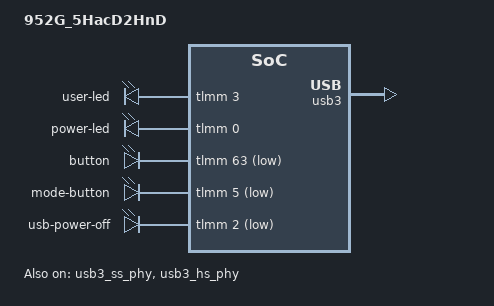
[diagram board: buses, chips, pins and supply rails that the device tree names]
/dts-v1/;
#include "ipq40xx.dtsi"

/ {
	model = "952G_5HacD2HnD";

	leds {
		compatible = "leds-rb";
		user-led {
			gpios = <&tlmm 3 GPIO_ACTIVE_HIGH>;
		};
		power-led {
			gpios = <&tlmm 0 GPIO_ACTIVE_HIGH>;
			default-state = "keep";
		};
		button {
			gpios = <&tlmm 63 GPIO_ACTIVE_LOW>;
			default-state = "input";
		};
		mode-button {
			gpios = <&tlmm 5 GPIO_ACTIVE_LOW>;
			default-state = "input";
		};
		usb-power-off {
			gpios = <&tlmm 2 GPIO_ACTIVE_LOW>;
		};
	};
};

&edma {
	port_map = <4 3 2 1 0(-1)>;
};

&usb3 {
	status = "ok";
};

&usb3_ss_phy {
	status = "ok";
};

&usb3_hs_phy {
	status = "ok";
};
